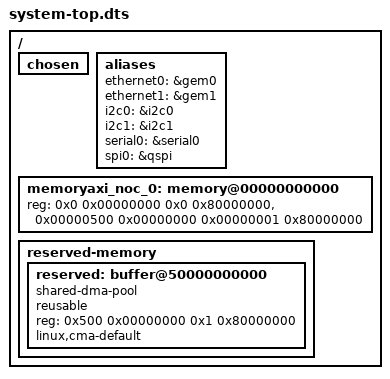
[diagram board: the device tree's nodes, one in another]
/*
 * CAUTION: This file is automatically generated by Xilinx.
 * Version:  
 * Today is: Sun Apr 11 20:52:46 2021
 */


/dts-v1/;
#include "versal.dtsi"
#include "versal-vck190-reva-x-ebm-01-reva.dtsi"
#include "versal-clk.dtsi"
#include "pcw.dtsi"
/ {
	chosen {
	};
	aliases {
		ethernet0 = &gem0;
		ethernet1 = &gem1;
		i2c0 = &i2c0;
		i2c1 = &i2c1;
		serial0 = &serial0;
		spi0 = &qspi;
	};
	memoryaxi_noc_0: memory@00000000000 {
		device_type = "memory";
		reg = <0x0 0x00000000 0x0 0x80000000>, <0x00000500 0x00000000 0x00000001 0x80000000>;
	};
	reserved-memory {
		#address-cells = <2>;
		#size-cells = <2>;
		ranges;

		reserved: buffer@50000000000 {
			compatible = "shared-dma-pool";
			reusable;
			reg = <0x500 0x00000000 0x1 0x80000000>;
			linux,cma-default;
		};
	};
};
#include "system-user.dtsi"
